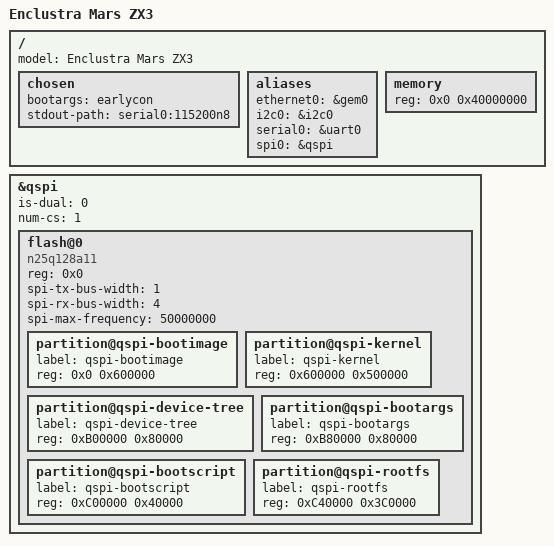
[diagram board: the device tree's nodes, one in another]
/*
 *  Copyright (C) 2011 - 2015 Xilinx
 *  Copyright (c) 2015 - 2018 Enclustra GmbH, Switzerland
 *
 * This software is licensed under the terms of the GNU General Public
 * License version 2, as published by the Free Software Foundation, and
 * may be copied, distributed, and modified under those terms.
 *
 * This program is distributed in the hope that it will be useful,
 * but WITHOUT ANY WARRANTY; without even the implied warranty of
 * MERCHANTABILITY or FITNESS FOR A PARTICULAR PURPOSE.  See the
 * GNU General Public License for more details.
 */


/dts-v1/;
/include/ "zynq-7000.dtsi"
/include/ "pl.dtsi"
/include/ "pcw.dtsi"
/include/ "system-user.dtsi"

/ {
	model = "Enclustra Mars ZX3";
	
	chosen {
		bootargs = "earlycon";
		stdout-path = "serial0:115200n8";
	};
	
	aliases {
		ethernet0 = &gem0;
		i2c0 = &i2c0;
		serial0 = &uart0;
		spi0 = &qspi;
	};

	memory {
		device_type = "memory";
		reg = <0x0 0x40000000>;
	};
};

&qspi {
	status = "okay";
	is-dual = <0>;
	num-cs = <1>;
	flash@0 {
		compatible = "n25q128a11";
		reg = <0x0>;
		spi-tx-bus-width = <1>;
		spi-rx-bus-width = <4>;
		spi-max-frequency = <50000000>;
		#address-cells = <1>;
		#size-cells = <1>;
		partition@qspi-bootimage {
			label = "qspi-bootimage";
			reg = <0x0 0x600000>;
		};
		partition@qspi-kernel {
			label = "qspi-kernel";
			reg = <0x600000 0x500000>;
		};
		partition@qspi-device-tree {
			label = "qspi-device-tree";
			reg = <0xB00000 0x80000>;
		};
		partition@qspi-bootargs {
			label = "qspi-bootargs";
			reg = <0xB80000 0x80000>;
		};
		partition@qspi-bootscript {
			label = "qspi-bootscript";
			reg = <0xC00000 0x40000>;
		};
		partition@qspi-rootfs {
			label = "qspi-rootfs";
			reg = <0xC40000 0x3C0000>;
		};
	};
};
